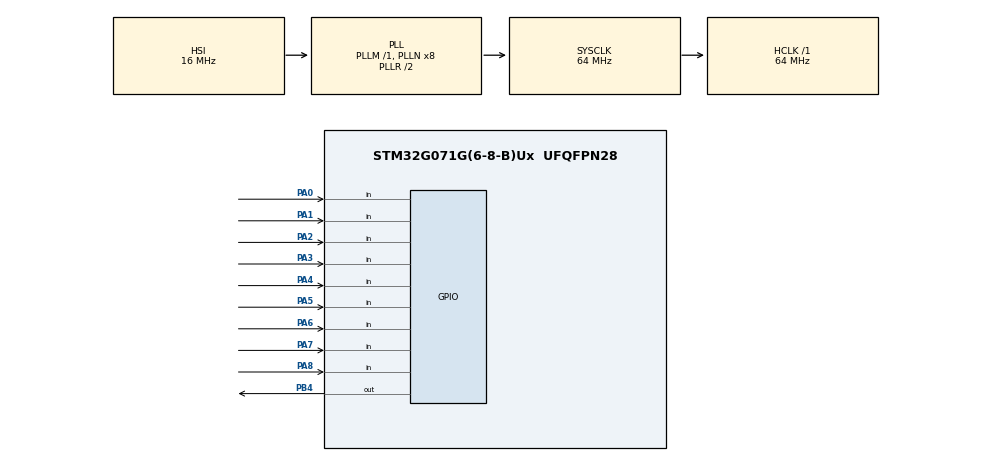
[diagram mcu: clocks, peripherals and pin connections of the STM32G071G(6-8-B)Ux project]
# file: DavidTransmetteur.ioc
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Mcu.Family=STM32G0
Mcu.Name=STM32G071G(6-8-B)Ux
Mcu.Package=UFQFPN28
PA0.GPIO_PuPd=GPIO_PULLDOWN
PA0.Signal=GPIO_Input
PA1.GPIO_PuPd=GPIO_PULLDOWN
PA1.Signal=GPIO_Input
PA2.GPIO_PuPd=GPIO_PULLDOWN
PA2.Signal=GPIO_Input
PA3.GPIO_PuPd=GPIO_PULLDOWN
PA3.Signal=GPIO_Input
PA4.GPIO_PuPd=GPIO_PULLDOWN
PA4.Signal=GPIO_Input
PA5.GPIO_PuPd=GPIO_PULLDOWN
PA5.Signal=GPIO_Input
PA6.GPIO_PuPd=GPIO_PULLDOWN
PA6.Signal=GPIO_Input
PA7.GPIO_PuPd=GPIO_PULLDOWN
PA7.Signal=GPIO_Input
PA8.GPIO_PuPd=GPIO_PULLDOWN
PA8.Signal=GPIO_Input
PB4.Signal=GPIO_Output
ProjectManager.HeapSize=0x200
ProjectManager.StackSize=0x400
ProjectManager.TargetToolchain=STM32CubeIDE
RCC.ADCFreq_Value=64000000
RCC.AHBFreq_Value=64000000
RCC.CortexFreq_Value=64000000
RCC.EXTERNAL_CLOCK_VALUE=48000
RCC.HCLKFreq_Value=64000000
RCC.HSE_VALUE=8000000
RCC.HSI_VALUE=16000000
RCC.LSE_VALUE=32768
RCC.SYSCLKFreq_VALUE=64000000
RCC.SYSCLKSource=RCC_SYSCLKSOURCE_PLLCLK
RCC.VCOOutputFreq_Value=128000000
TIM2.Prescaler=31
VP_TIM2_VS_ClockSourceINT.Mode=Internal
board=custom

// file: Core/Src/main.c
/* USER CODE BEGIN Header */
/**
  ******************************************************************************
  * @file           : main.c
  * @brief          : Main program body
  ******************************************************************************
  * @attention
  *
  * Copyright (c) 2026 STMicroelectronics.
  * All rights reserved.
  *
  * This software is licensed under terms that can be found in the LICENSE file
  * in the root directory of this software component.
  * If no LICENSE file comes with this software, it is provided AS-IS.
  *
  ******************************************************************************
  */
/* USER CODE END Header */
#include "main.h"

TIM_HandleTypeDef htim2;

void SystemClock_Config(void);
static void MX_GPIO_Init(void);
static void MX_TIM2_Init(void);

int main(void)
{

  /* MCU Configuration--------------------------------------------------------*/

  /* Reset of all peripherals, Initializes the Flash interface and the Systick. */
  HAL_Init();

  /* Configure the system clock */
  SystemClock_Config();

  /* Initialize all configured peripherals */
  MX_GPIO_Init();
  MX_TIM2_Init();

  /* Infinite loop */
  /* USER CODE BEGIN WHILE */
  extern void main_exe(void);
  main_exe();

  while (1)
  {
    /* USER CODE END WHILE */

  }
}

void SystemClock_Config(void)
{
  RCC_OscInitTypeDef RCC_OscInitStruct = {0};
  RCC_ClkInitTypeDef RCC_ClkInitStruct = {0};

  /** Configure the main internal regulator output voltage
  */
  HAL_PWREx_ControlVoltageScaling(PWR_REGULATOR_VOLTAGE_SCALE1);

  /** Initializes the RCC Oscillators according to the specified parameters
  * in the RCC_OscInitTypeDef structure.
  */
  RCC_OscInitStruct.OscillatorType = RCC_OSCILLATORTYPE_HSI;
  RCC_OscInitStruct.HSIState = RCC_HSI_ON;
  RCC_OscInitStruct.HSIDiv = RCC_HSI_DIV1;
  RCC_OscInitStruct.HSICalibrationValue = RCC_HSICALIBRATION_DEFAULT;
  RCC_OscInitStruct.PLL.PLLState = RCC_PLL_ON;
  RCC_OscInitStruct.PLL.PLLSource = RCC_PLLSOURCE_HSI;
  RCC_OscInitStruct.PLL.PLLM = RCC_PLLM_DIV1;
  RCC_OscInitStruct.PLL.PLLN = 8;
  RCC_OscInitStruct.PLL.PLLP = RCC_PLLP_DIV2;
  RCC_OscInitStruct.PLL.PLLQ = RCC_PLLQ_DIV2;
  RCC_OscInitStruct.PLL.PLLR = RCC_PLLR_DIV2;
  if (HAL_RCC_OscConfig(&RCC_OscInitStruct) != HAL_OK)
  {
    Error_Handler();
  }

  /** Initializes the CPU, AHB and APB buses clocks
  */
  RCC_ClkInitStruct.ClockType = RCC_CLOCKTYPE_HCLK|RCC_CLOCKTYPE_SYSCLK
                              |RCC_CLOCKTYPE_PCLK1;
  RCC_ClkInitStruct.SYSCLKSource = RCC_SYSCLKSOURCE_PLLCLK;
  RCC_ClkInitStruct.AHBCLKDivider = RCC_SYSCLK_DIV1;
  RCC_ClkInitStruct.APB1CLKDivider = RCC_HCLK_DIV1;

  if (HAL_RCC_ClockConfig(&RCC_ClkInitStruct, FLASH_LATENCY_2) != HAL_OK)
  {
    Error_Handler();
  }
}

static void MX_TIM2_Init(void)
{

  TIM_ClockConfigTypeDef sClockSourceConfig = {0};
  TIM_MasterConfigTypeDef sMasterConfig = {0};

  htim2.Instance = TIM2;
  htim2.Init.Prescaler = 31;
  htim2.Init.CounterMode = TIM_COUNTERMODE_UP;
  htim2.Init.Period = 4294967295;
  htim2.Init.ClockDivision = TIM_CLOCKDIVISION_DIV1;
  htim2.Init.AutoReloadPreload = TIM_AUTORELOAD_PRELOAD_DISABLE;
  if (HAL_TIM_Base_Init(&htim2) != HAL_OK)
  {
    Error_Handler();
  }
  sClockSourceConfig.ClockSource = TIM_CLOCKSOURCE_INTERNAL;
  if (HAL_TIM_ConfigClockSource(&htim2, &sClockSourceConfig) != HAL_OK)
  {
    Error_Handler();
  }
  sMasterConfig.MasterOutputTrigger = TIM_TRGO_RESET;
  sMasterConfig.MasterSlaveMode = TIM_MASTERSLAVEMODE_DISABLE;
  if (HAL_TIMEx_MasterConfigSynchronization(&htim2, &sMasterConfig) != HAL_OK)
  {
    Error_Handler();
  }

}

static void MX_GPIO_Init(void)
{
  GPIO_InitTypeDef GPIO_InitStruct = {0};

  /* GPIO Ports Clock Enable */
  __HAL_RCC_GPIOA_CLK_ENABLE();
  __HAL_RCC_GPIOB_CLK_ENABLE();

  /*Configure GPIO pin Output Level */
  HAL_GPIO_WritePin(GPIOB, GPIO_PIN_4, GPIO_PIN_RESET);

  /*Configure GPIO pins : PA0 PA1 PA2 PA3
                           PA4 PA5 PA6 PA7
                           PA8 */
  GPIO_InitStruct.Pin = GPIO_PIN_0|GPIO_PIN_1|GPIO_PIN_2|GPIO_PIN_3
                          |GPIO_PIN_4|GPIO_PIN_5|GPIO_PIN_6|GPIO_PIN_7
                          |GPIO_PIN_8;
  GPIO_InitStruct.Mode = GPIO_MODE_INPUT;
  GPIO_InitStruct.Pull = GPIO_PULLDOWN;
  HAL_GPIO_Init(GPIOA, &GPIO_InitStruct);

  /*Configure GPIO pin : PB4 */
  GPIO_InitStruct.Pin = GPIO_PIN_4;
  GPIO_InitStruct.Mode = GPIO_MODE_OUTPUT_PP;
  GPIO_InitStruct.Pull = GPIO_NOPULL;
  GPIO_InitStruct.Speed = GPIO_SPEED_FREQ_LOW;
  HAL_GPIO_Init(GPIOB, &GPIO_InitStruct);

}

void Error_Handler(void)
{
  __disable_irq();
  while (1)
  {
  }
}
